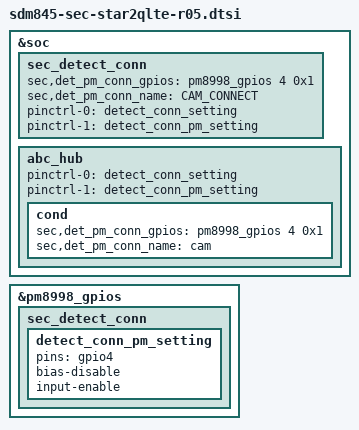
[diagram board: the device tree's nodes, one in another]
/* Copyright (c) 2016-2017, The Linux Foundation. All rights reserved.
 *
 * This program is free software; you can redistribute it and/or modify
 * it under the terms of the GNU General Public License version 2 and
 * only version 2 as published by the Free Software Foundation.
 *
 * This program is distributed in the hope that it will be useful,
 * but WITHOUT ANY WARRANTY; without even the implied warranty of
 * MERCHANTABILITY or FITNESS FOR A PARTICULAR PURPOSE.  See the
 * GNU General Public License for more details.
 */

#include "sdm845-sec-star2qlte-r04.dtsi"

&soc {
	sec_detect_conn {
		sec,det_pm_conn_gpios = <&pm8998_gpios 4 0x1>; /* CAM_DETECT */
		sec,det_pm_conn_name = "CAM_CONNECT";
		pinctrl-names = "det_ap_connect", "det_pm_connect";
		pinctrl-0 = <&detect_conn_setting>;
		pinctrl-1 = <&detect_conn_pm_setting>;
	};

	abc_hub {
		pinctrl-names = "det_ap_connect", "det_pm_connect";
		pinctrl-0 = <&detect_conn_setting>;
		pinctrl-1 = <&detect_conn_pm_setting>;

		cond {
			sec,det_pm_conn_gpios = <&pm8998_gpios 4 0x1>; /* CAM_DETECT */
			sec,det_pm_conn_name = "cam";
		};
	};
};

&pm8998_gpios {
	sec_detect_conn {
		detect_conn_pm_setting: detect_conn_pm_setting {
			pins = "gpio4";
			bias-disable; /* No PULL */
			input-enable;
		};
	};
};
